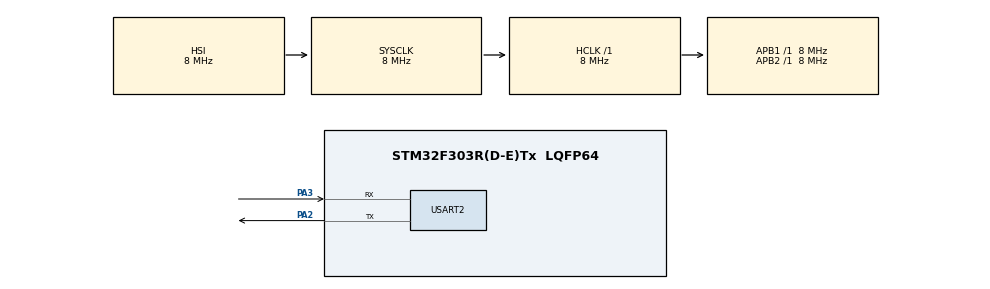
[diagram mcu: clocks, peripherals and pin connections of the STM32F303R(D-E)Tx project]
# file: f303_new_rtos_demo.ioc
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FREERTOS.Tasks01=fakeSensors,24,256,StartFakeSensors,Default,NULL,Static,fakeSensorsBuffer,fakeSensorsControlBlock;fakeTelemetry,8,256,StartFakeTelemetry,Default,NULL,Static,fakeTelemetryBuffer,fakeTelemetryControlBlock;fakeEjection,8,256,StartFakeEjection,Default,NULL,Static,fakeEjectionBuffer,fakeEjectionControlBlock
FREERTOS.configUSE_NEWLIB_REENTRANT=1
Mcu.Family=STM32F3
Mcu.Name=STM32F303R(D-E)Tx
Mcu.Package=LQFP64
NVIC.PriorityGroup=NVIC_PRIORITYGROUP_4
NVIC.TIM1_UP_TIM16_IRQn=true\:5\:0\:false\:false\:true\:true\:true\:true
NVIC.TIM6_DAC_IRQn=true\:15\:0\:false\:false\:true\:false\:false\:true
NVIC.TimeBase=TIM6_DAC_IRQn
NVIC.TimeBaseIP=TIM6
PA2.Mode=Asynchronous
PA2.Signal=USART2_TX
PA3.Mode=Asynchronous
PA3.Signal=USART2_RX
ProjectManager.HeapSize=0x200
ProjectManager.StackSize=0x400
ProjectManager.TargetToolchain=STM32CubeIDE
RCC.AHBFreq_Value=8000000
RCC.APB1Freq_Value=8000000
RCC.APB2Freq_Value=8000000
RCC.CortexFreq_Value=8000000
RCC.HSE_VALUE=8000000
RCC.HSI_VALUE=8000000
RCC.LSE_VALUE=32768
RCC.SYSCLKFreq_VALUE=8000000
RCC.USBFreq_Value=16000000
RTC.Alarm-Alarm\ A=RTC_ALARM_A
RTC.AlarmMaskHours-Alarm\ A=RTC_ALARMMASK_HOURS
RTC.AlarmMaskHours_B-Alarm\ B=RTC_ALARMMASK_HOURS
RTC.Alarm_B-Alarm\ B=RTC_ALARM_B
RTC.Minutes=29
RTC.Minutes_A-Alarm\ A=30
RTC.Minutes_B-Alarm\ B=33
TIM16.Period=14999
TIM16.Prescaler=7999
USART2.VirtualMode-Asynchronous=VM_ASYNC
VP_FREERTOS_VS_CMSIS_V2.Mode=CMSIS_V2
VP_RTC_VS_RTC_Activate.Mode=RTC_Enabled
VP_RTC_VS_RTC_Alarm_A_Intern.Mode=Alarm A
VP_RTC_VS_RTC_Alarm_B_Intern.Mode=Alarm B
VP_RTC_VS_RTC_Calendar.Mode=RTC_Calendar
VP_SYS_VS_tim6.Mode=TIM6
VP_TIM16_VS_ClockSourceINT.Mode=Enable_Timer
board=custom

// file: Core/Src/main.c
/* USER CODE BEGIN Header */
/**
 ******************************************************************************
 * @file           : main.c
 * @brief          : Main program body
 ******************************************************************************
 * @attention
 *
 * <h2><center>&copy; Copyright (c) 2021 STMicroelectronics.
 * All rights reserved.</center></h2>
 *
 * This software component is licensed by ST under Ultimate Liberty license
 * SLA0044, the "License"; You may not use this file except in compliance with
 * the License. You may obtain a copy of the License at:-
 *                             www.st.com/SLA0044
 *
 ******************************************************************************
 */
/* USER CODE END Header */
#include "main.h"
#include "cmsis_os.h"

/* USER CODE BEGIN Includes */
#include <string.h>
#include <stdio.h>
/* USER CODE END Includes */

typedef StaticTask_t osStaticThreadDef_t;

RTC_HandleTypeDef hrtc;

TIM_HandleTypeDef htim16;

UART_HandleTypeDef huart2;

/* Definitions for fakeSensors */
osThreadId_t fakeSensorsHandle;
uint32_t fakeSensorsBuffer[256];
osStaticThreadDef_t fakeSensorsControlBlock;
const osThreadAttr_t fakeSensors_attributes = { .name = "fakeSensors", .cb_mem =
		&fakeSensorsControlBlock, .cb_size = sizeof(fakeSensorsControlBlock),
		.stack_mem = &fakeSensorsBuffer[0], .stack_size =
				sizeof(fakeSensorsBuffer), .priority =
				(osPriority_t) osPriorityNormal, };
/* Definitions for fakeTelemetry */
osThreadId_t fakeTelemetryHandle;
uint32_t fakeTelemetryBuffer[256];
osStaticThreadDef_t fakeTelemetryControlBlock;
const osThreadAttr_t fakeTelemetry_attributes = { .name = "fakeTelemetry",
		.cb_mem = &fakeTelemetryControlBlock, .cb_size =
				sizeof(fakeTelemetryControlBlock), .stack_mem =
				&fakeTelemetryBuffer[0], .stack_size =
				sizeof(fakeTelemetryBuffer), .priority =
				(osPriority_t) osPriorityLow, };
/* Definitions for fakeEjection */
osThreadId_t fakeEjectionHandle;
uint32_t fakeEjectionBuffer[256];
osStaticThreadDef_t fakeEjectionControlBlock;
const osThreadAttr_t fakeEjection_attributes = { .name = "fakeEjection",
		.cb_mem = &fakeEjectionControlBlock, .cb_size =
				sizeof(fakeEjectionControlBlock), .stack_mem =
				&fakeEjectionBuffer[0],
		.stack_size = sizeof(fakeEjectionBuffer), .priority =
				(osPriority_t) osPriorityLow, };
/* USER CODE BEGIN PV */
// rtc variables
RTC_DateTypeDef sdatestructureget;
RTC_TimeTypeDef stimestructureget;
RTC_AlarmTypeDef sAlarmA;
RTC_AlarmTypeDef sAlarmB;

// flag to indicate alarmA interrupt occurred
volatile uint8_t alarmAOccurred = 0;
char msg[100];

float acceleration;
uint32_t numberOfFriends = 0; // :(
/* USER CODE END PV */

void SystemClock_Config(void);
static void MX_GPIO_Init(void);
static void MX_USART2_UART_Init(void);
static void MX_TIM16_Init(void);
static void MX_RTC_Init(void);
void StartFakeSensors(void *argument);
void StartFakeTelemetry(void *argument);
void StartFakeEjection(void *argument);

/* USER CODE BEGIN PFP */
void myprintf(char *buffer) {
	HAL_UART_Transmit(&huart2, (uint8_t*) buffer, 100, 100);
}
/* USER CODE END PFP */

int main(void) {

	/* MCU Configuration--------------------------------------------------------*/

	/* Reset of all peripherals, Initializes the Flash interface and the Systick. */
	HAL_Init();

	/* Configure the system clock */
	SystemClock_Config();

	/* Initialize all configured peripherals */
	MX_GPIO_Init();
	MX_USART2_UART_Init();
	MX_TIM16_Init();
	MX_RTC_Init();
	/* USER CODE BEGIN 2 */
	HAL_TIM_Base_Start_IT(&htim16);

	/* USER CODE END 2 */

	/* Init scheduler */
	osKernelInitialize();

	/* Create the thread(s) */
	/* creation of fakeSensors */
	fakeSensorsHandle = osThreadNew(StartFakeSensors, NULL,
			&fakeSensors_attributes);

	/* creation of fakeTelemetry */
	fakeTelemetryHandle = osThreadNew(StartFakeTelemetry, NULL,
			&fakeTelemetry_attributes);

	/* creation of fakeEjection */
	fakeEjectionHandle = osThreadNew(StartFakeEjection, NULL,
			&fakeEjection_attributes);

	/* Start scheduler */
	osKernelStart();

	/* We should never get here as control is now taken by the scheduler */
	/* Infinite loop */
	while (1) {

	}
}

void SystemClock_Config(void) {
	RCC_OscInitTypeDef RCC_OscInitStruct = { 0 };
	RCC_ClkInitTypeDef RCC_ClkInitStruct = { 0 };
	RCC_PeriphCLKInitTypeDef PeriphClkInit = { 0 };

	/** Initializes the RCC Oscillators according to the specified parameters
	 * in the RCC_OscInitTypeDef structure.
	 */
	RCC_OscInitStruct.OscillatorType = RCC_OSCILLATORTYPE_HSI
			| RCC_OSCILLATORTYPE_LSI;
	RCC_OscInitStruct.HSIState = RCC_HSI_ON;
	RCC_OscInitStruct.HSICalibrationValue = RCC_HSICALIBRATION_DEFAULT;
	RCC_OscInitStruct.LSIState = RCC_LSI_ON;
	RCC_OscInitStruct.PLL.PLLState = RCC_PLL_NONE;
	if (HAL_RCC_OscConfig(&RCC_OscInitStruct) != HAL_OK) {
		Error_Handler();
	}
	/** Initializes the CPU, AHB and APB buses clocks
	 */
	RCC_ClkInitStruct.ClockType = RCC_CLOCKTYPE_HCLK | RCC_CLOCKTYPE_SYSCLK
			| RCC_CLOCKTYPE_PCLK1 | RCC_CLOCKTYPE_PCLK2;
	RCC_ClkInitStruct.SYSCLKSource = RCC_SYSCLKSOURCE_HSI;
	RCC_ClkInitStruct.AHBCLKDivider = RCC_SYSCLK_DIV1;
	RCC_ClkInitStruct.APB1CLKDivider = RCC_HCLK_DIV1;
	RCC_ClkInitStruct.APB2CLKDivider = RCC_HCLK_DIV1;

	if (HAL_RCC_ClockConfig(&RCC_ClkInitStruct, FLASH_LATENCY_0) != HAL_OK) {
		Error_Handler();
	}
	PeriphClkInit.PeriphClockSelection = RCC_PERIPHCLK_USART2
			| RCC_PERIPHCLK_RTC | RCC_PERIPHCLK_TIM16;
	PeriphClkInit.Usart2ClockSelection = RCC_USART2CLKSOURCE_PCLK1;
	PeriphClkInit.RTCClockSelection = RCC_RTCCLKSOURCE_LSI;
	PeriphClkInit.Tim16ClockSelection = RCC_TIM16CLK_HCLK;
	if (HAL_RCCEx_PeriphCLKConfig(&PeriphClkInit) != HAL_OK) {
		Error_Handler();
	}
}

static void MX_RTC_Init(void) {

	RTC_TimeTypeDef sTime = { 0 };
	RTC_DateTypeDef sDate = { 0 };
	RTC_AlarmTypeDef sAlarm = { 0 };

	/** Initialize RTC Only
	 */
	hrtc.Instance = RTC;
	hrtc.Init.HourFormat = RTC_HOURFORMAT_24;
	hrtc.Init.AsynchPrediv = 127;
	hrtc.Init.SynchPrediv = 255;
	hrtc.Init.OutPut = RTC_OUTPUT_DISABLE;
	hrtc.Init.OutPutPolarity = RTC_OUTPUT_POLARITY_HIGH;
	hrtc.Init.OutPutType = RTC_OUTPUT_TYPE_OPENDRAIN;
	if (HAL_RTC_Init(&hrtc) != HAL_OK) {
		Error_Handler();
	}

	/** Initialize RTC and set the Time and Date
	 */
	sTime.Hours = 0x0;
	sTime.Minutes = 0x29;
	sTime.Seconds = 0x0;
	sTime.DayLightSaving = RTC_DAYLIGHTSAVING_NONE;
	sTime.StoreOperation = RTC_STOREOPERATION_RESET;
	if (HAL_RTC_SetTime(&hrtc, &sTime, RTC_FORMAT_BCD) != HAL_OK) {
		Error_Handler();
	}
	sDate.WeekDay = RTC_WEEKDAY_MONDAY;
	sDate.Month = RTC_MONTH_JANUARY;
	sDate.Date = 0x1;
	sDate.Year = 0x0;

	if (HAL_RTC_SetDate(&hrtc, &sDate, RTC_FORMAT_BCD) != HAL_OK) {
		Error_Handler();
	}
	/** Enable the Alarm A
	 */
	sAlarm.AlarmTime.Hours = 0x0;
	sAlarm.AlarmTime.Minutes = 0x30;
	sAlarm.AlarmTime.Seconds = 0x0;
	sAlarm.AlarmTime.SubSeconds = 0x0;
	sAlarm.AlarmTime.DayLightSaving = RTC_DAYLIGHTSAVING_NONE;
	sAlarm.AlarmTime.StoreOperation = RTC_STOREOPERATION_RESET;
	sAlarm.AlarmMask = RTC_ALARMMASK_HOURS;
	sAlarm.AlarmSubSecondMask = RTC_ALARMSUBSECONDMASK_ALL;
	sAlarm.AlarmDateWeekDaySel = RTC_ALARMDATEWEEKDAYSEL_DATE;
	sAlarm.AlarmDateWeekDay = 0x1;
	sAlarm.Alarm = RTC_ALARM_A;
	if (HAL_RTC_SetAlarm(&hrtc, &sAlarm, RTC_FORMAT_BCD) != HAL_OK) {
		Error_Handler();
	}
	/** Enable the Alarm B
	 */

	sAlarm.AlarmTime.Minutes = 0x31;
	sAlarm.Alarm = RTC_ALARM_B;

	/* USER CODE BEGIN RTC_Init 2 */
	sAlarm.AlarmTime.DayLightSaving = RTC_DAYLIGHTSAVING_NONE;
	sAlarm.AlarmTime.StoreOperation = RTC_STOREOPERATION_RESET;
	sAlarm.AlarmMask = RTC_ALARMMASK_HOURS;
	sAlarm.AlarmSubSecondMask = RTC_ALARMSUBSECONDMASK_ALL;
	sAlarm.AlarmDateWeekDaySel = RTC_ALARMDATEWEEKDAYSEL_DATE;
	sAlarm.AlarmDateWeekDay = 0x1;
	if (HAL_RTC_SetAlarm(&hrtc, &sAlarm, RTC_FORMAT_BCD) != HAL_OK) {
		Error_Handler();
	}
	/* USER CODE END RTC_Init 2 */

}

static void MX_TIM16_Init(void) {

	htim16.Instance = TIM16;
	htim16.Init.Prescaler = 7999;
	htim16.Init.CounterMode = TIM_COUNTERMODE_UP;
	htim16.Init.Period = 14999;
	htim16.Init.ClockDivision = TIM_CLOCKDIVISION_DIV1;
	htim16.Init.RepetitionCounter = 0;
	htim16.Init.AutoReloadPreload = TIM_AUTORELOAD_PRELOAD_DISABLE;
	if (HAL_TIM_Base_Init(&htim16) != HAL_OK) {
		Error_Handler();
	}

}

static void MX_USART2_UART_Init(void) {

	huart2.Instance = USART2;
	huart2.Init.BaudRate = 38400;
	huart2.Init.WordLength = UART_WORDLENGTH_8B;
	huart2.Init.StopBits = UART_STOPBITS_1;
	huart2.Init.Parity = UART_PARITY_NONE;
	huart2.Init.Mode = UART_MODE_TX_RX;
	huart2.Init.HwFlowCtl = UART_HWCONTROL_NONE;
	huart2.Init.OverSampling = UART_OVERSAMPLING_16;
	huart2.Init.OneBitSampling = UART_ONE_BIT_SAMPLE_DISABLE;
	huart2.AdvancedInit.AdvFeatureInit = UART_ADVFEATURE_NO_INIT;
	if (HAL_UART_Init(&huart2) != HAL_OK) {
		Error_Handler();
	}

}

static void MX_GPIO_Init(void) {

	/* GPIO Ports Clock Enable */
	__HAL_RCC_GPIOA_CLK_ENABLE();

}

/* USER CODE BEGIN 4 */
// Callbacks
void HAL_RTC_AlarmAEventCallback(RTC_HandleTypeDef *hrtc) {
	sprintf((char*) msg, "Alarm A callback entered\r\n");
	HAL_UART_Transmit(&huart2, (uint8_t*) msg, strlen((char const*) msg), 1000);
	sprintf((char*) msg, "alarmA flag: %d\talarmB flag: %d\r\n\n",
			__HAL_RTC_ALARM_GET_FLAG(hrtc, RTC_FLAG_ALRAF),
			__HAL_RTC_ALARM_GET_FLAG(hrtc, RTC_FLAG_ALRBF));
	HAL_UART_Transmit(&huart2, (uint8_t*) msg, strlen(msg), 1000);
	// clear the alarm flag
	__HAL_RTC_WRITEPROTECTION_DISABLE(hrtc);
	while (__HAL_RTC_ALARM_GET_FLAG(hrtc, RTC_FLAG_ALRAF) != RESET)
		__HAL_RTC_ALARM_CLEAR_FLAG(hrtc, RTC_FLAG_ALRAF);
	__HAL_RTC_WRITEPROTECTION_ENABLE(hrtc);
	__HAL_RTC_ALARM_EXTI_CLEAR_FLAG();

	sprintf((char*) msg, "alarmA flag after clear: %d\talarmB flag: %d\r\n\n",
			__HAL_RTC_ALARM_GET_FLAG(hrtc, RTC_FLAG_ALRAF),
			__HAL_RTC_ALARM_GET_FLAG(hrtc, RTC_FLAG_ALRBF));
	HAL_UART_Transmit(&huart2, (uint8_t*) msg, strlen(msg), 1000);
	alarmAOccurred = 1;

	  __HAL_PWR_CLEAR_FLAG(PWR_FLAG_WU);
	  HAL_SuspendTick(); // systick generates interrupts which may wake the processor
	  HAL_PWR_EnterSTOPMode(PWR_MAINREGULATOR_ON, PWR_STOPENTRY_WFI);
}

void HAL_RTCEx_AlarmBEventCallback(RTC_HandleTypeDef *hrtc) {

	sprintf((char*) msg, "Alarm B callback entered\r\n");
	HAL_UART_Transmit(&huart2, (uint8_t*) msg, strlen((char const*) msg), 1000);

	HAL_UART_Transmit(&huart2, (uint8_t*) msg, strlen((char const*) msg), 1000);
	sprintf((char*) msg,
			"before clear attempt: alarmA flag: %d\talarmB flag: %d\r\n\n",
			__HAL_RTC_ALARM_GET_FLAG(hrtc, RTC_FLAG_ALRAF),
			__HAL_RTC_ALARM_GET_FLAG(hrtc, RTC_FLAG_ALRBF));
	HAL_UART_Transmit(&huart2, (uint8_t*) msg, strlen(msg), 1000);

	// clear the alarm flag
	__HAL_RTC_WRITEPROTECTION_DISABLE(hrtc);
	while (__HAL_RTC_ALARM_GET_FLAG(hrtc, RTC_FLAG_ALRBF) != RESET)
		__HAL_RTC_ALARM_CLEAR_FLAG(hrtc, RTC_FLAG_ALRBF);
	__HAL_RTC_ALARM_EXTI_CLEAR_FLAG();
	__HAL_RTC_WRITEPROTECTION_ENABLE(hrtc);
	__HAL_RTC_ALARM_EXTI_CLEAR_FLAG();

	sprintf((char*) msg,
			"after clear attempt: alarmA flag: %d\talarmB flag: %d\r\n\n",
			__HAL_RTC_ALARM_GET_FLAG(hrtc, RTC_FLAG_ALRAF),
			__HAL_RTC_ALARM_GET_FLAG(hrtc, RTC_FLAG_ALRBF));
	HAL_UART_Transmit(&huart2, (uint8_t*) msg, strlen(msg), 1000);
	alarmAOccurred = 1;

	__HAL_PWR_CLEAR_FLAG(PWR_FLAG_WU);
	HAL_SuspendTick(); // systick generates interrupts which may wake the processor

}

//void HAL_TIM_PeriodElapsedCallback(TIM_HandleTypeDef *htim) {
//	if (htim == &htim16) {
//		sprintf((char*) msg, "TIM16 callback entered\r\n");
//		HAL_UART_Transmit(&huart2, (uint8_t*) msg, strlen((char const*) msg),
//				1000);
//
//
//		// print current RTC time for debugging
//		HAL_RTC_GetTime(&hrtc, &stimestructureget, RTC_FORMAT_BIN);
//		HAL_RTC_GetDate(&hrtc, &sdatestructureget, RTC_FORMAT_BIN);
//		sprintf((char*) msg, "main, current: GetTime/Date: %.2d:%.2d:%.2d\r\n",
//				stimestructureget.Hours, stimestructureget.Minutes,
//				stimestructureget.Seconds);
//		HAL_UART_Transmit(&huart2, (uint8_t*) msg, strlen(msg), 1000);
//
////		// print status of alarm flags for debugging
//		sprintf((char*) msg, "alarmA flag: %d\talarmB flag: %d\r\n\n",
//				__HAL_RTC_ALARM_GET_FLAG(&hrtc, RTC_FLAG_ALRAF),
//				__HAL_RTC_ALARM_GET_FLAG(&hrtc, RTC_FLAG_ALRBF));
//		HAL_UART_Transmit(&huart2, (uint8_t*) msg, strlen(msg), 1000);
//	}
//}

/*
 * polls the alarm interrupt flags and calls the appropriate callback functions.
 */
void pollAlarmInterruptFlag(void) {
	if (__HAL_RTC_ALARM_GET_FLAG(&hrtc, RTC_FLAG_ALRAF) != RESET)
		HAL_RTC_AlarmAEventCallback(&hrtc);
	if (__HAL_RTC_ALARM_GET_FLAG(&hrtc, RTC_FLAG_ALRBF) != RESET)
		HAL_RTCEx_AlarmBEventCallback(&hrtc);
}
/* USER CODE END 4 */

void StartFakeSensors(void *argument) {
	/* USER CODE BEGIN 5 */
	/* Infinite loop */
	float accels[10] = { 0.0, 0.23, 120.0, 420.0, 69.42, 10.3, 20.5, 12.12,
			42.42, 0.0 };
	uint32_t friends[10] = { 0, 1, 2, 3, 4, 5, 4, 3, 2, 1 };
	/* Infinite loop */
	uint32_t i = 0;
	char *buffer = (char*) malloc(100);
	memset(buffer, 0, 100);
	for (;;) {

		acceleration = accels[i % 10];
		numberOfFriends = friends[i % 10];
		sprintf(buffer, "IN Acceleration: %f\r\n", acceleration);
		myprintf(buffer);
		sprintf(buffer, "IN Number of friends: %lu\r\n", numberOfFriends);
		myprintf(buffer);
		++i;
		osDelay(2000);

	}
	/* USER CODE END 5 */
}

void StartFakeTelemetry(void *argument) {
	/* USER CODE BEGIN StartFakeTelemetry */
	/* Infinite loop */
	char *buffer1 = (char*) malloc(100);
	memset(buffer1, 0, 100);
	for (;;) {

		sprintf(buffer1, "OUT Acceleration: %f\r\n", acceleration);
		myprintf(buffer1);
		sprintf(buffer1, "OUT Number of friends: %li\r\n", numberOfFriends);
		myprintf(buffer1);
		osDelay(5000);

	}
	/* USER CODE END StartFakeTelemetry */
}

void StartFakeEjection(void *argument) {
	/* USER CODE BEGIN StartFakeEjection */
	/* Infinite loop */
	char *buffer = (char*) malloc(100);
	memset(buffer, 0, 100);
	for (;;) {

		if (numberOfFriends == 5) {
			sprintf(buffer, "EJECT or smthg\r\n");
			myprintf(buffer);
		}
		osDelay(1000);

	}
	/* USER CODE END StartFakeEjection */
}

void HAL_TIM_PeriodElapsedCallback(TIM_HandleTypeDef *htim) {
	if (htim->Instance == TIM6) {
		HAL_IncTick();
	}
	/* USER CODE BEGIN Callback 1 */
	if (htim->Instance == TIM16) {
		pollAlarmInterruptFlag();
		char *buffer = (char*) malloc(100);
		memset(buffer, 0, 100);
		sprintf(buffer, "UwU\r\n");
		myprintf(buffer);
//		HAL_Delay(10000);
		sprintf(buffer, "wUw\r\n");
		myprintf(buffer);
	}
	/* USER CODE END Callback 1 */
}

void Error_Handler(void) {
	__disable_irq();
	while (1) {
	}
}

/************************ (C) COPYRIGHT STMicroelectronics *****END OF FILE****/
